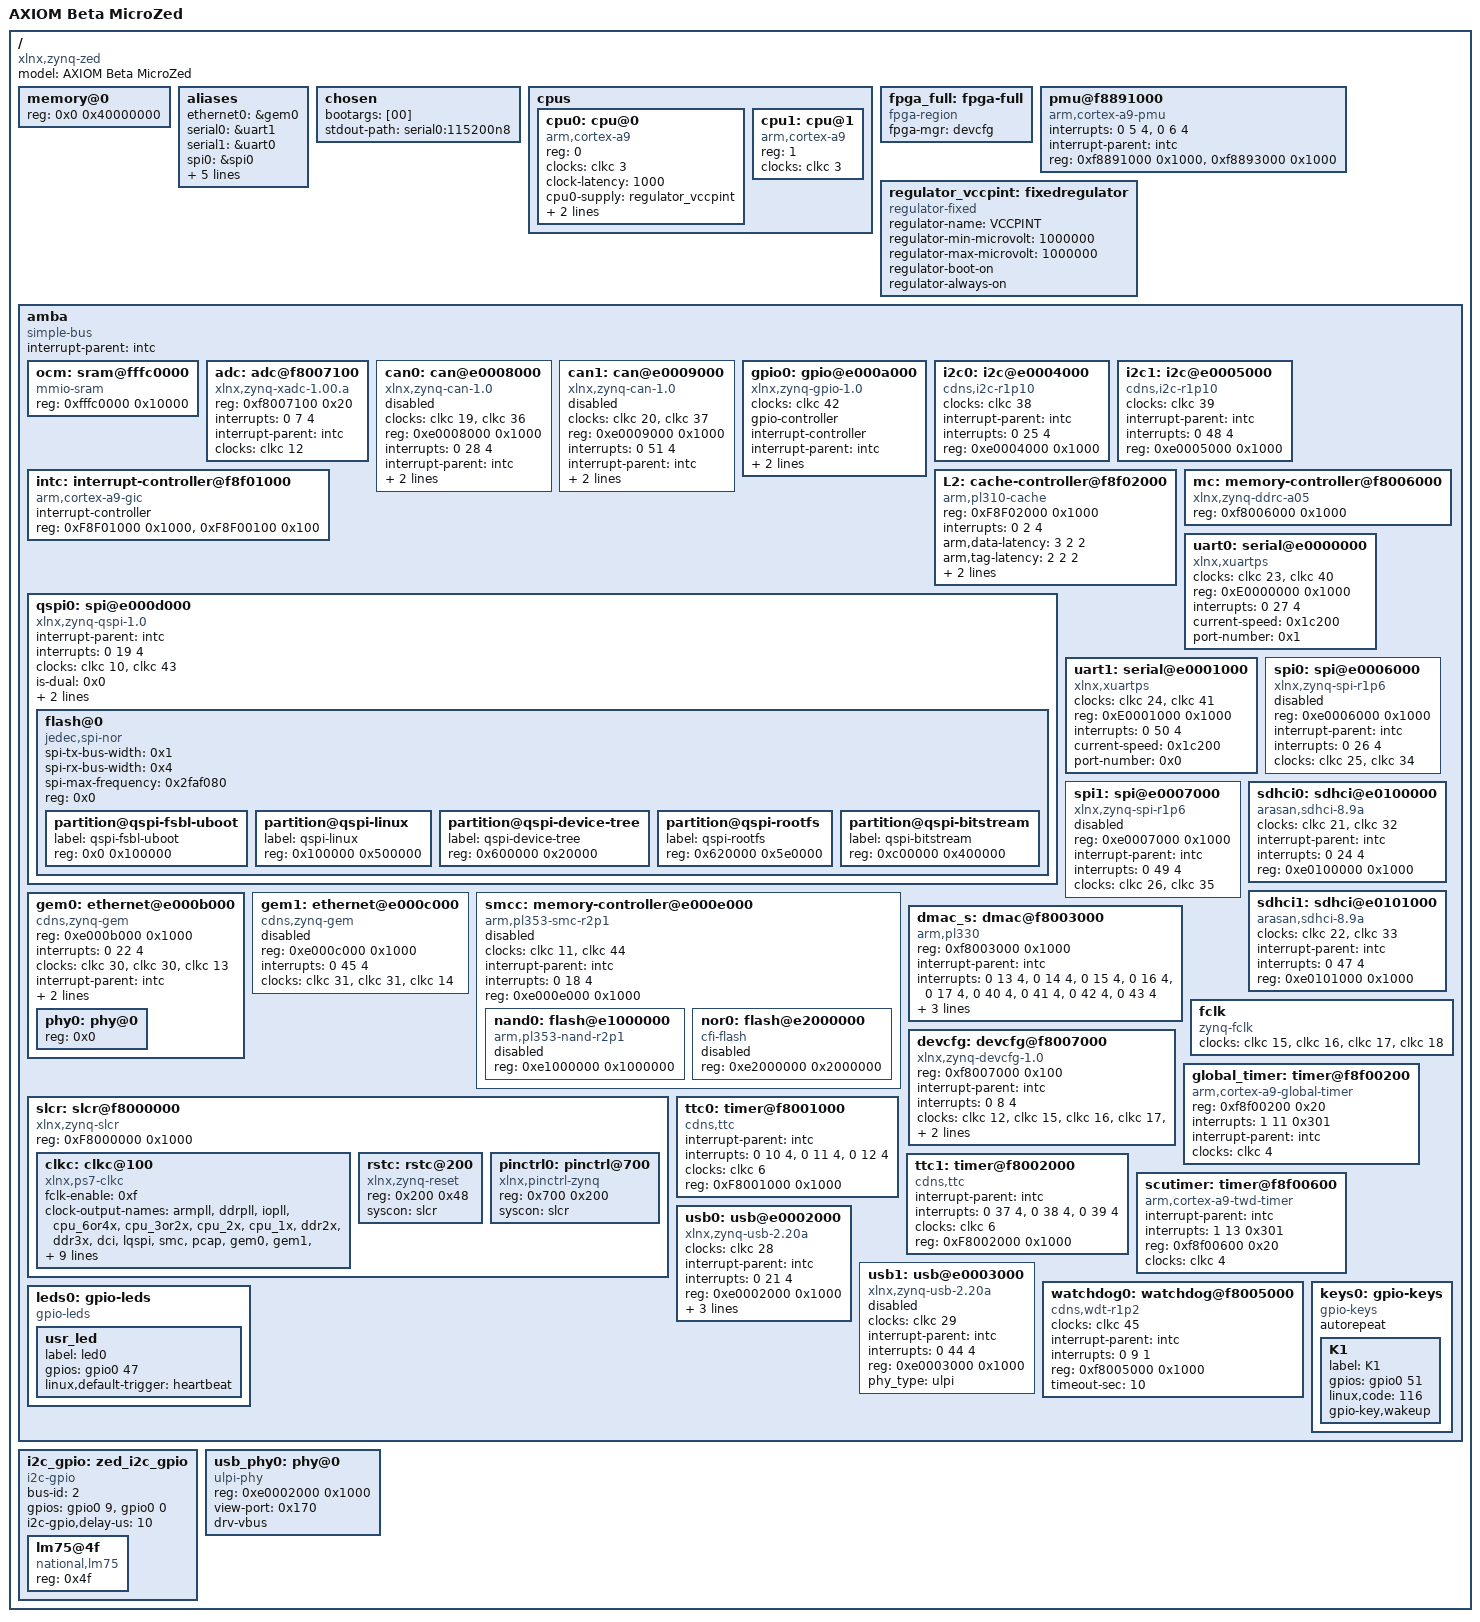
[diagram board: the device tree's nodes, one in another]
/*
 * AXIOM Beta MicroZed Device Tree
 * Version 1.3
 *
 * Copyright (C) 2014-2017 H.Poetzl
 * Copyright (C) 2018-2019 R.Heinemann
 *
 * This program is free software: you can redistribute it and/or
 * modify it under the terms of the GNU General Public License
 * as published by the Free Software Foundation, either version
 * 2 of the License, or (at your option) any later version.
 *
 * http://devicetree.org/Device_Tree_Usage
 * Power_ePAPR_APPROVED_v1.1.pdf
 *
 * scripts/dtc/dtc -I dts -O dtb -o devicetree.dtb devicetree.dts
 *
 */

/dts-v1/;

/ {
	#address-cells = <1>;
	#size-cells = <1>;
    compatible = "xlnx,zynq-zed", "xlnx,zynq-7000";
    model = "AXIOM Beta MicroZed";

	memory@0 {
		device_type = "memory";
		reg = <0x0 0x40000000>;
	};

	aliases {
		ethernet0 = &gem0;
		serial0 = &uart1;
		serial1 = &uart0;
		spi0 = &spi0;
		spi1 = &spi1;
		mmc0 = &sdhci0;
        i2c0 = &i2c_gpio;
        i2c1 = &i2c0;
        i2c2 = &i2c1;
	};

	chosen {
		bootargs = [00];
//		bootargs = "bootargs=console=ttyPS0,115200n8 root=/dev/mmcblk0p2 rw rootfstype=ext4 rootwait debug verbose systemd.log_level=warning systemd.log_target=console kernel.sysrq=1 init=/usr/lib/systemd/systemd sdhci.debug_quirks=64 earlycon";
		stdout-path = "serial0:115200n8";
	};

	cpus {
		#address-cells = <1>;
		#size-cells = <0>;

		cpu0: cpu@0 {
			compatible = "arm,cortex-a9";
			device_type = "cpu";
			reg = <0>;
			clocks = <&clkc 3>;
			clock-latency = <1000>;
			cpu0-supply = <&regulator_vccpint>;
			operating-points = <
				/* kHz    uV */
				666667  1000000
				333334  1000000
			>;
		};

		cpu1: cpu@1 {
			compatible = "arm,cortex-a9";
			device_type = "cpu";
			reg = <1>;
			clocks = <&clkc 3>;
		};
	};

	fpga_full: fpga-full {
		compatible = "fpga-region";
		fpga-mgr = <&devcfg>;
		#address-cells = <1>;
		#size-cells = <1>;
		ranges;
	};

	pmu@f8891000 {
		compatible = "arm,cortex-a9-pmu";
		interrupts = <0 5 4>, <0 6 4>;
		interrupt-parent = <&intc>;
		reg = <0xf8891000 0x1000>,
		      <0xf8893000 0x1000>;
	};

	regulator_vccpint: fixedregulator {
		compatible = "regulator-fixed";
		regulator-name = "VCCPINT";
		regulator-min-microvolt = <1000000>;
		regulator-max-microvolt = <1000000>;
		regulator-boot-on;
		regulator-always-on;
	};

	amba: amba {
		compatible = "simple-bus";
		#address-cells = <1>;
		#size-cells = <1>;
		interrupt-parent = <&intc>;
		ranges;

        ocm: sram@fffc0000 {
		    compatible = "mmio-sram";
		    reg = <0xfffc0000 0x10000>;
	    };


		adc: adc@f8007100 {
			compatible = "xlnx,zynq-xadc-1.00.a";
			reg = <0xf8007100 0x20>;
			interrupts = <0 7 4>;
			interrupt-parent = <&intc>;
			clocks = <&clkc 12>;
		};

		can0: can@e0008000 {
			compatible = "xlnx,zynq-can-1.0";
			status = "disabled";
			clocks = <&clkc 19>, <&clkc 36>;
			clock-names = "can_clk", "pclk";
			reg = <0xe0008000 0x1000>;
			interrupts = <0 28 4>;
			interrupt-parent = <&intc>;
			tx-fifo-depth = <0x40>;
			rx-fifo-depth = <0x40>;
		};

		can1: can@e0009000 {
			compatible = "xlnx,zynq-can-1.0";
			status = "disabled";
			clocks = <&clkc 20>, <&clkc 37>;
			clock-names = "can_clk", "pclk";
			reg = <0xe0009000 0x1000>;
			interrupts = <0 51 4>;
			interrupt-parent = <&intc>;
			tx-fifo-depth = <0x40>;
			rx-fifo-depth = <0x40>;
		};

		gpio0: gpio@e000a000 {
			compatible = "xlnx,zynq-gpio-1.0";
			#gpio-cells = <2>;
			clocks = <&clkc 42>;
			gpio-controller;
			interrupt-controller;
			#interrupt-cells = <2>;
			interrupt-parent = <&intc>;
			interrupts = <0 20 4>;
			reg = <0xe000a000 0x1000>;
		};

		i2c0: i2c@e0004000 {
			compatible = "cdns,i2c-r1p10";
			status = "okay";
			clocks = <&clkc 38>;
			interrupt-parent = <&intc>;
			interrupts = <0 25 4>;
			reg = <0xe0004000 0x1000>;
			#address-cells = <1>;
			#size-cells = <0>;
		};

		i2c1: i2c@e0005000 {
			compatible = "cdns,i2c-r1p10";
			status = "okay";
			clocks = <&clkc 39>;
			interrupt-parent = <&intc>;
			interrupts = <0 48 4>;
			reg = <0xe0005000 0x1000>;
			#address-cells = <1>;
			#size-cells = <0>;
		};

		intc: interrupt-controller@f8f01000 {
			compatible = "arm,cortex-a9-gic";
			#interrupt-cells = <3>;
			interrupt-controller;
			reg = <0xF8F01000 0x1000>,
			      <0xF8F00100 0x100>;
		};

		L2: cache-controller@f8f02000 {
			compatible = "arm,pl310-cache";
			reg = <0xF8F02000 0x1000>;
			interrupts = <0 2 4>;
			arm,data-latency = <3 2 2>;
			arm,tag-latency = <2 2 2>;
			cache-unified;
			cache-level = <2>;
		};

		qspi0: spi@e000d000 {
			compatible = "xlnx,zynq-qspi-1.0";
			#address-cells = <0x1>;
			#size-cells = <0x0>;
			status = "okay";
			interrupt-parent = <&intc>;
			interrupts = <0 19 4>;
			clock-names = "ref_clk", "pclk";
			clocks = <&clkc 10>,  <&clkc 43>;
			is-dual = <0x0>;
			num-cs = <0x1>;
			reg = <0xe000d000 0x1000>;

			flash@0 {
				compatible = "jedec,spi-nor";
				#address-cells = <0x1>;
				#size-cells = <0x1>;
				spi-tx-bus-width = <0x1>;
				spi-rx-bus-width = <0x4>;
				spi-max-frequency = <0x2faf080>;
				reg = <0x0>;

				partition@qspi-fsbl-uboot {
					label = "qspi-fsbl-uboot";
					reg = <0x0 0x100000>;
				};

				partition@qspi-linux {
					label = "qspi-linux";
					reg = <0x100000 0x500000>;
				};

				partition@qspi-device-tree {
					label = "qspi-device-tree";
					reg = <0x600000 0x20000>;
				};

				partition@qspi-rootfs {
					label = "qspi-rootfs";
					reg = <0x620000 0x5e0000>;
				};

				partition@qspi-bitstream {
					label = "qspi-bitstream";
					reg = <0xc00000 0x400000>;
				};
			};
		};

		mc: memory-controller@f8006000 {
			compatible = "xlnx,zynq-ddrc-a05";
			reg = <0xf8006000 0x1000>;
		};

		uart0: serial@e0000000 {
			compatible = "xlnx,xuartps", "cdns,uart-r1p8";
			status = "okay";
			clocks = <&clkc 23>, <&clkc 40>;
			clock-names = "uart_clk", "pclk";
			reg = <0xE0000000 0x1000>;
			interrupts = <0 27 4>;
			current-speed = <0x1c200>;
			port-number = <0x1>;
		};

		uart1: serial@e0001000 {
			compatible = "xlnx,xuartps", "cdns,uart-r1p8";
			status = "okay";
			clocks = <&clkc 24>, <&clkc 41>;
			clock-names = "uart_clk", "pclk";
			reg = <0xE0001000 0x1000>;
			interrupts = <0 50 4>;
			current-speed = <0x1c200>;
			port-number = <0x0>;
		};

		spi0: spi@e0006000 {
			compatible = "xlnx,zynq-spi-r1p6";
			reg = <0xe0006000 0x1000>;
			status = "disabled";
			interrupt-parent = <&intc>;
			interrupts = <0 26 4>;
			clocks = <&clkc 25>, <&clkc 34>;
			clock-names = "ref_clk", "pclk";
			#address-cells = <1>;
			#size-cells = <0>;
		};

		spi1: spi@e0007000 {
			compatible = "xlnx,zynq-spi-r1p6";
			reg = <0xe0007000 0x1000>;
			status = "disabled";
			interrupt-parent = <&intc>;
			interrupts = <0 49 4>;
			clocks = <&clkc 26>, <&clkc 35>;
			clock-names = "ref_clk", "pclk";
			#address-cells = <1>;
			#size-cells = <0>;
		};

		gem0: ethernet@e000b000 {
			compatible = "cdns,zynq-gem", "cdns,gem";
			reg = <0xe000b000 0x1000>;
			status = "okay";
			interrupts = <0 22 4>;
			clocks = <&clkc 30>, <&clkc 30>, <&clkc 13>;
			clock-names = "pclk", "hclk", "tx_clk";
			#address-cells = <1>;
			#size-cells = <0>;

			// local-mac-address = [00 0a 35 00 00 00];
			interrupt-parent = <&intc>;


			phy-mode = "rgmii-id";
			phy-handle = <&phy0>;

			phy0: phy@0 {
				reg = <0x0>;
			};
		};

		gem1: ethernet@e000c000 {
			compatible = "cdns,zynq-gem", "cdns,gem";
			reg = <0xe000c000 0x1000>;
			status = "disabled";
			interrupts = <0 45 4>;
			clocks = <&clkc 31>, <&clkc 31>, <&clkc 14>;
			clock-names = "pclk", "hclk", "tx_clk";
			#address-cells = <1>;
			#size-cells = <0>;
		};

		smcc: memory-controller@e000e000 {
			#address-cells = <1>;
			#size-cells = <1>;
			status = "disabled";
			clock-names = "memclk", "aclk";
			clocks = <&clkc 11>, <&clkc 44>;
			compatible = "arm,pl353-smc-r2p1";
			interrupt-parent = <&intc>;
			interrupts = <0 18 4>;
			ranges ;
			reg = <0xe000e000 0x1000>;
			nand0: flash@e1000000 {
				status = "disabled";
				compatible = "arm,pl353-nand-r2p1";
				reg = <0xe1000000 0x1000000>;
				#address-cells = <0x1>;
				#size-cells = <0x1>;
			};
			nor0: flash@e2000000 {
				status = "disabled";
				compatible = "cfi-flash";
				reg = <0xe2000000 0x2000000>;
				#address-cells = <1>;
				#size-cells = <1>;
			};
		};


		sdhci0: sdhci@e0100000 {
			compatible = "arasan,sdhci-8.9a";
			status = "okay";
			clock-names = "clk_xin", "clk_ahb";
			clocks = <&clkc 21>, <&clkc 32>;
			interrupt-parent = <&intc>;
			interrupts = <0 24 4>;
			reg = <0xe0100000 0x1000>;
		};

		sdhci1: sdhci@e0101000 {
			compatible = "arasan,sdhci-8.9a";
			status = "okay";
			clock-names = "clk_xin", "clk_ahb";
			clocks = <&clkc 22>, <&clkc 33>;
			interrupt-parent = <&intc>;
			interrupts = <0 47 4>;
			reg = <0xe0101000 0x1000>;
		};

		slcr: slcr@f8000000 {
			#address-cells = <1>;
			#size-cells = <1>;
			compatible = "xlnx,zynq-slcr", "syscon", "simple-mfd";
			reg = <0xF8000000 0x1000>;
			ranges;
			clkc: clkc@100 {
				#clock-cells = <1>;
				compatible = "xlnx,ps7-clkc";
				fclk-enable = <0xf>;
				clock-output-names = "armpll", "ddrpll", "iopll", "cpu_6or4x",
						"cpu_3or2x", "cpu_2x", "cpu_1x", "ddr2x", "ddr3x",
						"dci", "lqspi", "smc", "pcap", "gem0", "gem1",
						"fclk0", "fclk1", "fclk2", "fclk3", "can0", "can1",
						"sdio0", "sdio1", "uart0", "uart1", "spi0", "spi1",
						"dma", "usb0_aper", "usb1_aper", "gem0_aper",
						"gem1_aper", "sdio0_aper", "sdio1_aper",
						"spi0_aper", "spi1_aper", "can0_aper", "can1_aper",
						"i2c0_aper", "i2c1_aper", "uart0_aper", "uart1_aper",
						"gpio_aper", "lqspi_aper", "smc_aper", "swdt",
						"dbg_trc", "dbg_apb";
				reg = <0x100 0x100>;
			};

			rstc: rstc@200 {
				compatible = "xlnx,zynq-reset";
				reg = <0x200 0x48>;
				#reset-cells = <1>;
				syscon = <&slcr>;
			};

			pinctrl0: pinctrl@700 {
				compatible = "xlnx,pinctrl-zynq";
				reg = <0x700 0x200>;
				syscon = <&slcr>;
			};
		};

		dmac_s: dmac@f8003000 {
			compatible = "arm,pl330", "arm,primecell";
			reg = <0xf8003000 0x1000>;
			interrupt-parent = <&intc>;
			interrupt-names = "abort", "dma0", "dma1", "dma2", "dma3",
				"dma4", "dma5", "dma6", "dma7";
			interrupts = <0 13 4>,
			             <0 14 4>, <0 15 4>,
			             <0 16 4>, <0 17 4>,
			             <0 40 4>, <0 41 4>,
			             <0 42 4>, <0 43 4>;
			#dma-cells = <1>;
			#dma-channels = <8>;
			#dma-requests = <4>;
			clocks = <&clkc 27>;
			clock-names = "apb_pclk";
		};

		devcfg: devcfg@f8007000 {
			compatible = "xlnx,zynq-devcfg-1.0";
			reg = <0xf8007000 0x100>;
			interrupt-parent = <&intc>;
			interrupts = <0 8 4>;
			clocks = <&clkc 12>, <&clkc 15>, <&clkc 16>, <&clkc 17>, <&clkc 18>;
			clock-names = "ref_clk", "fclk0", "fclk1", "fclk2", "fclk3";
			syscon = <&slcr>;
		};

		fclk: fclk {
			compatible = "zynq-fclk";
			clocks = <&clkc 15>, <&clkc 16>, <&clkc 17>, <&clkc 18>;
			clock-names = "fclk0", "fclk1", "fclk2", "fclk3";
		};

		global_timer: timer@f8f00200 {
			compatible = "arm,cortex-a9-global-timer";
			reg = <0xf8f00200 0x20>;
			interrupts = <1 11 0x301>;
			interrupt-parent = <&intc>;
			clocks = <&clkc 4>;
		};

		ttc0: timer@f8001000 {
			interrupt-parent = <&intc>;
			interrupts = <0 10 4>, <0 11 4>, <0 12 4>;
			compatible = "cdns,ttc";
			clocks = <&clkc 6>;
			reg = <0xF8001000 0x1000>;
		};

		ttc1: timer@f8002000 {
			interrupt-parent = <&intc>;
			interrupts = <0 37 4>, <0 38 4>, <0 39 4>;
			compatible = "cdns,ttc";
			clocks = <&clkc 6>;
			reg = <0xF8002000 0x1000>;
		};

		scutimer: timer@f8f00600 {
			interrupt-parent = <&intc>;
			interrupts = <1 13 0x301>;
			compatible = "arm,cortex-a9-twd-timer";
			reg = <0xf8f00600 0x20>;
			clocks = <&clkc 4>;
		};

		usb0: usb@e0002000 {
			compatible = "xlnx,zynq-usb-2.20a", "chipidea,usb2";
			status = "okay";
			clocks = <&clkc 28>;
			interrupt-parent = <&intc>;
			interrupts = <0 21 4>;
			reg = <0xe0002000 0x1000>;
			phy_type = "ulpi";
			dr_mode = "host";
			usb-phy = <&usb_phy0>;
		};

		usb1: usb@e0003000 {
			compatible = "xlnx,zynq-usb-2.20a", "chipidea,usb2";
			status = "disabled";
			clocks = <&clkc 29>;
			interrupt-parent = <&intc>;
			interrupts = <0 44 4>;
			reg = <0xe0003000 0x1000>;
			phy_type = "ulpi";
		};

		watchdog0: watchdog@f8005000 {
			clocks = <&clkc 45>;
			compatible = "cdns,wdt-r1p2";
			interrupt-parent = <&intc>;
			interrupts = <0 9 1>;
			reg = <0xf8005000 0x1000>;
			timeout-sec = <10>;
		};


		leds0: gpio-leds {
			compatible = "gpio-leds";

			usr_led {
				label = "led0";
				gpios = <&gpio0 47 0>;
				linux,default-trigger = "heartbeat";
			};
		};

		keys0: gpio-keys {
			compatible = "gpio-keys";
			autorepeat;

			K1 {
				label = "K1";
				gpios = <&gpio0 51 0>;
				linux,code = <116>; /* KEY_POWER */
				gpio-key,wakeup;
				// autorepeat;
			};
		};


	};

	i2c_gpio: zed_i2c_gpio {
		#address-cells = <1>;
		#size-cells = <0>;
		compatible = "i2c-gpio";
		bus-id = <2>;
		gpios = <&gpio0 9 0 /* sda */
		         &gpio0 0 0 /* scl */ >;

		/* i2c-gpio,sda-open-drain; */
		/* i2c-gpio,scl-open-drain; */
		/* i2c-gpio,delay-us = <5>; /* ~100 kHz */
		i2c-gpio,delay-us = <10>;   /* ~50 kHz */

		/*
		mcp23018@20 {
			#gpio-cells = <2>;
			gpio-controller ;
			compatible = "microchip,mcp23017";
			reg = <0x20>;
		};
		mcp23018@21 {
			#gpio-cells = <2>;
			gpio-controller ;
			compatible = "microchip,mcp23017";
			reg = <0x21>;
		};
		mcp23018@22 {
			#gpio-cells = <2>;
			gpio-controller ;
			compatible = "microchip,mcp23017";
			reg = <0x22>;
		};
		mcp23018@23 {
			#gpio-cells = <2>;
			gpio-controller ;
			compatible = "microchip,mcp23017";
			reg = <0x23>;
		};  */

		lm75@4f {
			#gpio-cells = <2>;
			compatible = "national,lm75";
			reg = <0x4f>;
		};
	};

    usb_phy0: phy@0 {
		compatible = "ulpi-phy";
		#phy-cells = <0x0>;
		reg = <0xe0002000 0x1000>;
		view-port = <0x170>;
		drv-vbus;
    };
};
